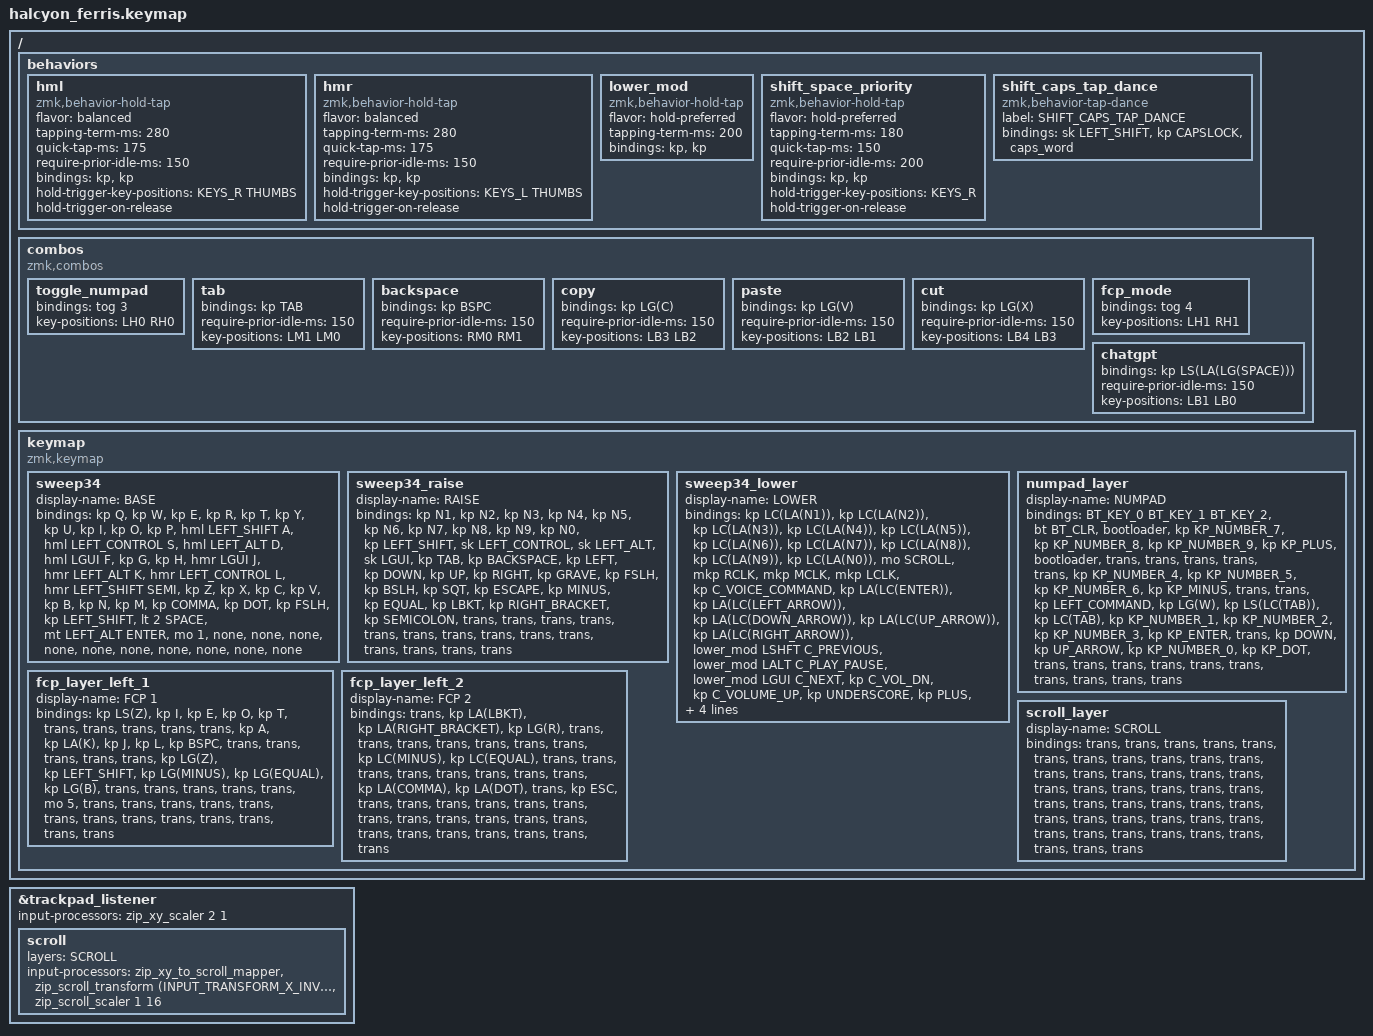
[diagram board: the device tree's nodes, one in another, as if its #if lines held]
/*
 * Halcyon Ferris (splitkb.com) keymap.
 *
 * Ported from splitkb_aurora_sweep.keymap: same 34-key layout, HRMs and
 * combos. The Halcyon Ferris physical layout registers 44 positions: 34 keys
 * plus a trailing row of 10 slots reserved for Halcyon module buttons
 * (encoder push etc.), so every layer is padded with 10 extra bindings.
 *
 * The dongle is the split central and the only part that evaluates this
 * keymap; the halves only need it to parse.
 */

#include <behaviors.dtsi>
#include <dt-bindings/zmk/bt.h>
#include <dt-bindings/zmk/ext_power.h>
#include <dt-bindings/zmk/keys.h>
#include <dt-bindings/zmk/outputs.h>
#include <dt-bindings/zmk/input_transform.h>
#include <dt-bindings/zmk/pointing.h>

#include <input/processors.dtsi>
#include <dt-bindings/zmk/split_mode.h>

#include "zmk-helpers/helper.h"
#include "zmk-helpers/key-labels/34.h"

/* Dual-role builds (HALCYON_DUAL_ROLE via -DDTS_EXTRA_CPPFLAGS) switch dongle/standalone mode with
 * the BT keys; every other build keeps plain profile selection.
 * These keys must stay on the LEFT half: the dongle records the slot the press came from as the
 * standalone half. */
#ifdef HALCYON_DUAL_ROLE
#define BT_KEY_0 &split_mode SM_DONGLE
#define BT_KEY_1 &split_mode SM_HOST 1
#define BT_KEY_2 &split_mode SM_HOST 2
#else
#define BT_KEY_0 &bt BT_SEL 0
#define BT_KEY_1 &bt BT_SEL 1
#define BT_KEY_2 &bt BT_SEL 2
#endif

#define KEYS_L LT0 LT1 LT2 LT3 LT4 LM0 LM1 LM2 LM3 LM4 LB0 LB1 LB2 LB3 LB4 
#define KEYS_R RT0 RT1 RT2 RT3 RT4 RM0 RM1 RM2 RM3 RM4 RB0 RB1 RB2 RB3 RB4 
#define THUMBS LH1 LH0 RH0 RH1

#define SCROLL 6

/*
 * Cirque touchpad (right half) is forwarded to the split central, which runs
 * this listener. Scale X/Y deltas by 2/1 (multiplier/divisor); tweak the
 * ratio to taste. Leave the hardware `sensitivity` at the module's "2x":
 * "1x" saturates the sensor and it stops reporting touches.
 *
 * Tap-to-click is disabled in halcyon_ferris_right.overlay; mouse keys live
 * on the LOWER layer's left home row: A = scroll (hold), S = right click,
 * D = middle click, F = left click. With A not held the pad moves the
 * pointer as usual, so clicks land where it points. The row below keeps its
 * media keys on tap but holds a modifier for click/drag combos:
 * Z = Shift, X = Alt, C = Cmd (see `lower_mod`).
 *
 * Layer override: SCROLL turns pad movement into wheel events on both axes
 * (swipe sideways to scroll horizontally). The scroll scaler's divisor sets
 * how many pad units make one wheel line; raise it to slow scrolling down.
 * The transform flips the wheel direction (raw Cirque deltas scroll
 * backwards).
 */
&trackpad_listener {
    input-processors = <&zip_xy_scaler 2 1>;

    scroll {
        layers = <SCROLL>;
        input-processors = <&zip_xy_to_scroll_mapper>,
                           <&zip_scroll_transform (INPUT_TRANSFORM_X_INVERT | INPUT_TRANSFORM_Y_INVERT)>,
                           <&zip_scroll_scaler 1 16>;
    };
};

/* left-hand HRMs */
ZMK_HOLD_TAP(hml,
    flavor = "balanced";
    tapping-term-ms = <280>;
    quick-tap-ms = <175>;                // repeat on tap-into-hold
    require-prior-idle-ms = <150>;
    bindings = <&kp>, <&kp>;
    hold-trigger-key-positions = <KEYS_R THUMBS>;
    hold-trigger-on-release;             // delay positional check until key-release
)

/* right-hand HRMs */
ZMK_HOLD_TAP(hmr,
    flavor = "balanced";
    tapping-term-ms = <280>;
    quick-tap-ms = <175>;                // repeat on tap-into-hold
    require-prior-idle-ms = <150>;
    bindings = <&kp>, <&kp>;
    hold-trigger-key-positions = <KEYS_L THUMBS>;
    hold-trigger-on-release;             // delay positional check until key-release
)

/*
 * LOWER bottom row: tap = media key, hold = modifier for touchpad clicks.
 * Hold-preferred so the modifier is down as soon as a click key is pressed;
 * no positional restriction since the click keys are on the same hand.
 */
ZMK_HOLD_TAP(lower_mod,
    flavor = "hold-preferred";
    tapping-term-ms = <200>;
    bindings = <&kp>, <&kp>;
)

ZMK_HOLD_TAP(shift_space_priority,
    flavor = "hold-preferred";
    tapping-term-ms = <180>;    // Adjust based on typing speed
    quick-tap-ms = <150>;       // Max time between taps for double-tap
    require-prior-idle-ms = <200>; // Avoid misfires after fast typing
    bindings = <&kp>, <&kp>;
    hold-trigger-key-positions = <KEYS_R>; // Only trigger Shift if right-hand keys are pressed
    hold-trigger-on-release;    // Finalize hold/tap decision on key release
)

/ {
    behaviors {
        shift_caps_tap_dance: shift_caps_tap_dance {
            compatible = "zmk,behavior-tap-dance";
            label = "SHIFT_CAPS_TAP_DANCE";
            #binding-cells = <0>;
            bindings = <&sk LEFT_SHIFT>, <&kp CAPSLOCK>, <&caps_word>;
        };
    };

    combos {
        compatible = "zmk,combos";

        toggle_numpad {
            bindings = <&tog 3>;
            key-positions = <LH0 RH0>;
        };

        tab {
            bindings = <&kp TAB>;
            require-prior-idle-ms = <150>;
            key-positions = <LM1 LM0>;
        };

        backspace {
            bindings = <&kp BSPC>;
            require-prior-idle-ms = <150>;
            key-positions = <RM0 RM1>;
        };

        copy {
            bindings = <&kp LG(C)>;
            require-prior-idle-ms = <150>;
            key-positions = <LB3 LB2>;
        };

        paste {
            bindings = <&kp LG(V)>;
            require-prior-idle-ms = <150>;
            key-positions = <LB2 LB1>;
        };

        cut {
            bindings = <&kp LG(X)>;
            require-prior-idle-ms = <150>;
            key-positions = <LB4 LB3>;
        };

        fcp_mode {
            bindings = <&tog 4>;
            key-positions = <LH1 RH1>;
        };

        chatgpt {
            bindings = <&kp LS(LA(LG(SPACE)))>;
            require-prior-idle-ms = <150>;
            key-positions = <LB1 LB0>;
        };
    };

    keymap {
        compatible = "zmk,keymap";

        sweep34 {
            display-name = "BASE";
            bindings = <
&kp Q               &kp W                 &kp E             &kp R         &kp T               &kp Y      &kp U        &kp I                &kp O                  &kp P
&hml LEFT_SHIFT A   &hml LEFT_CONTROL S   &hml LEFT_ALT D   &hml LGUI F   &kp G               &kp H      &hmr LGUI J  &hmr LEFT_ALT K      &hmr LEFT_CONTROL L    &hmr LEFT_SHIFT SEMI
&kp Z               &kp X                 &kp C             &kp V         &kp B               &kp N      &kp M        &kp COMMA            &kp DOT                &kp FSLH
                                          &kp LEFT_SHIFT    &lt 2 SPACE   &mt LEFT_ALT ENTER  &mo 1

                /* Halcyon module slots (unused) */
                &none  &none  &none  &none  &none    &none  &none  &none  &none  &none
            >;
        };

        sweep34_raise {
            display-name = "RAISE";
            bindings = <
&kp N1                &kp N2            &kp N3        &kp N4    &kp N5        &kp N6         &kp N7     &kp N8    &kp N9             &kp N0
&kp LEFT_SHIFT        &sk LEFT_CONTROL  &sk LEFT_ALT  &sk LGUI  &kp TAB       &kp BACKSPACE  &kp LEFT   &kp DOWN  &kp UP             &kp RIGHT
&kp GRAVE             &kp FSLH          &kp BSLH      &kp SQT   &kp ESCAPE    &kp MINUS      &kp EQUAL  &kp LBKT  &kp RIGHT_BRACKET  &kp SEMICOLON
                                                      &trans    &trans        &trans         &trans

                /* Halcyon module slots (unused) */
                &trans &trans &trans &trans &trans   &trans &trans &trans &trans &trans
            >;
        };

        sweep34_lower {
            display-name = "LOWER";
            bindings = <
&kp LC(LA(N1))    &kp LC(LA(N2))        &kp LC(LA(N3))                &kp LC(LA(N4))                &kp LC(LA(N5))                  &kp LC(LA(N6))     &kp LC(LA(N7))          &kp LC(LA(N8))          &kp LC(LA(N9))        &kp LC(LA(N0))
&mo SCROLL        &mkp RCLK             &mkp MCLK                     &mkp LCLK                     &kp C_VOICE_COMMAND             &kp LA(LC(ENTER))  &kp LA(LC(LEFT_ARROW))  &kp LA(LC(DOWN_ARROW))  &kp LA(LC(UP_ARROW))  &kp LA(LC(RIGHT_ARROW))
&lower_mod LSHFT C_PREVIOUS  &lower_mod LALT C_PLAY_PAUSE  &lower_mod LGUI C_NEXT  &kp C_VOL_DN  &kp C_VOLUME_UP                 &kp UNDERSCORE     &kp PLUS                &kp LEFT_BRACE          &kp RIGHT_BRACE       &kp COLON
                                                                      &trans                        &trans                          &kp LEFT_SHIFT             &trans

                /* Halcyon module slots (unused) */
                &trans &trans &trans &trans &trans   &trans &trans &trans &trans &trans
            >;
        };

        numpad_layer {
            display-name = "NUMPAD";
            bindings = <
BT_KEY_0           BT_KEY_1          BT_KEY_2      &bt BT_CLR       &bootloader     &kp KP_NUMBER_7  &kp KP_NUMBER_8  &kp KP_NUMBER_9  &kp KP_PLUS   &bootloader
&trans             &trans            &trans        &trans           &trans          &kp KP_NUMBER_4  &kp KP_NUMBER_5  &kp KP_NUMBER_6  &kp KP_MINUS  &trans
&trans             &kp LEFT_COMMAND  &kp LG(W)     &kp LS(LC(TAB))  &kp LC(TAB)     &kp KP_NUMBER_1  &kp KP_NUMBER_2  &kp KP_NUMBER_3  &kp KP_ENTER  &trans
                                                   &kp DOWN         &kp UP_ARROW    &kp KP_NUMBER_0  &kp KP_DOT

                /* Halcyon module slots (unused) */
                &trans &trans &trans &trans &trans   &trans &trans &trans &trans &trans
            >;
        };

        fcp_layer_left_1 {
            display-name = "FCP 1";
            bindings = <
&kp LS(Z)  &kp I           &kp E          &kp O          &kp T        &trans  &trans  &trans  &trans  &trans
&kp A      &kp LA(K)       &kp J          &kp L          &kp BSPC     &trans  &trans  &trans  &trans  &trans
&kp LG(Z)  &kp LEFT_SHIFT  &kp LG(MINUS)  &kp LG(EQUAL)  &kp LG(B)    &trans  &trans  &trans  &trans  &trans
                                          &mo 5          &trans       &trans  &trans

                /* Halcyon module slots (unused) */
                &trans &trans &trans &trans &trans   &trans &trans &trans &trans &trans
            >;
        };

        fcp_layer_left_2 {
            display-name = "FCP 2";
            bindings = <
&trans  &kp LA(LBKT)   &kp LA(RIGHT_BRACKET)  &kp LG(R)  &trans     &trans  &trans  &trans  &trans  &trans
&trans  &kp LC(MINUS)  &kp LC(EQUAL)          &trans     &trans     &trans  &trans  &trans  &trans  &trans
&trans  &kp LA(COMMA)  &kp LA(DOT)            &trans     &kp ESC    &trans  &trans  &trans  &trans  &trans
                                              &trans     &trans     &trans  &trans

                /* Halcyon module slots (unused) */
                &trans &trans &trans &trans &trans   &trans &trans &trans &trans &trans
            >;
        };

        /* Held via A on LOWER: touchpad scrolls instead of moving the pointer. */
        scroll_layer {
            display-name = "SCROLL";
            bindings = <
&trans  &trans  &trans  &trans  &trans    &trans  &trans  &trans  &trans  &trans
&trans  &trans  &trans  &trans  &trans    &trans  &trans  &trans  &trans  &trans
&trans  &trans  &trans  &trans  &trans    &trans  &trans  &trans  &trans  &trans
                        &trans  &trans    &trans  &trans

                /* Halcyon module slots (unused) */
                &trans &trans &trans &trans &trans   &trans &trans &trans &trans &trans
            >;
        };
    };
};
